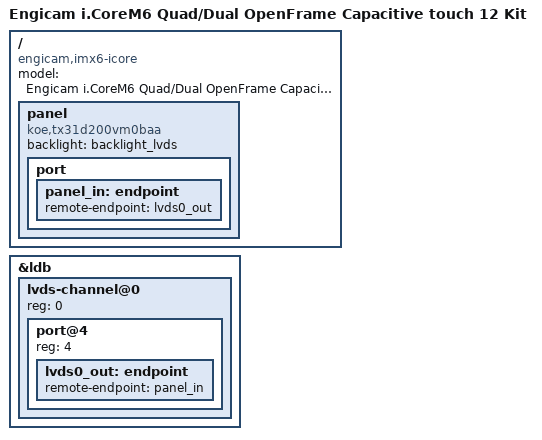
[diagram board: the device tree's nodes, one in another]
// SPDX-License-Identifier: (GPL-2.0+ OR MIT)
/*
 * Copyright (C) 2016 Amarula Solutions B.V.
 * Copyright (C) 2016 Engicam S.r.l.
 */

/dts-v1/;

#include "imx6q.dtsi"
#include "imx6qdl-icore.dtsi"

/ {
	model = "Engicam i.CoreM6 Quad/Dual OpenFrame Capacitive touch 12 Kit";
	compatible = "engicam,imx6-icore", "fsl,imx6q";

	panel {
		compatible = "koe,tx31d200vm0baa";
		backlight = <&backlight_lvds>;

		port {
			panel_in: endpoint {
				remote-endpoint = <&lvds0_out>;
			};
		};
	};
};

&ldb {
	status = "okay";

	lvds-channel@0 {
		reg = <0>;
		status = "okay";

		port@4 {
			reg = <4>;

			lvds0_out: endpoint {
				remote-endpoint = <&panel_in>;
			};
		};
	};
};
